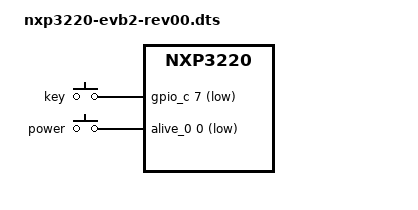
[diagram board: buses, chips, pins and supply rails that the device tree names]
// SPDX-License-Identifier: (GPL-2.0+ OR MIT)
/*
 * Copyright (C) 2018  Nexell Co., Ltd.
 * Author: JungHyun, Kim <jhkim@nexell.co.kr>
 */

/dts-v1/;

#include "nxp3220-evb2-common.dtsi"

/ {
	compatible = "nexell,nxp3220-evb2", "nexell,nxp3220";
};

&dwmmc_1 {
	status = "disabled";
};

&gpio_keys {
	pinctrl-names = "default";
	pinctrl-0 = <&button_key>, <&button_pwr>;

	button@key {
		label = "key";
		gpios = <&gpio_c 7 GPIO_ACTIVE_LOW>;
		linux,code = <KEY_BACK>;
	};

	button@pwr {
		label = "power";
		gpios = <&alive_0 0 GPIO_ACTIVE_LOW>;
		linux,code = <KEY_POWER>;
		gpio-key,wakeup;
	};
};
